# apollo4b register map
Vendor: Ambiq Micro; Series: Apollo; File version: 1.0
CPU: CM4 r1p0, little endian, MPU, FPU, I-cache, D-cache, VTOR, ITCM, DTCM, 3 interrupt priority bits, 0 interrupts
Registers are 32-bit, read-write, reset 0x0 unless marked. A register's access mark holds for its fields unless they carry their own. Offsets are from the block's base; [hi:lo] are bit positions; {n}, {i} and the like mark numbered series; 'fields as' and 'values as' point back to an identical list.

## GPIO (part 2 of 4) — General Purpose IO
Base 0x40010000
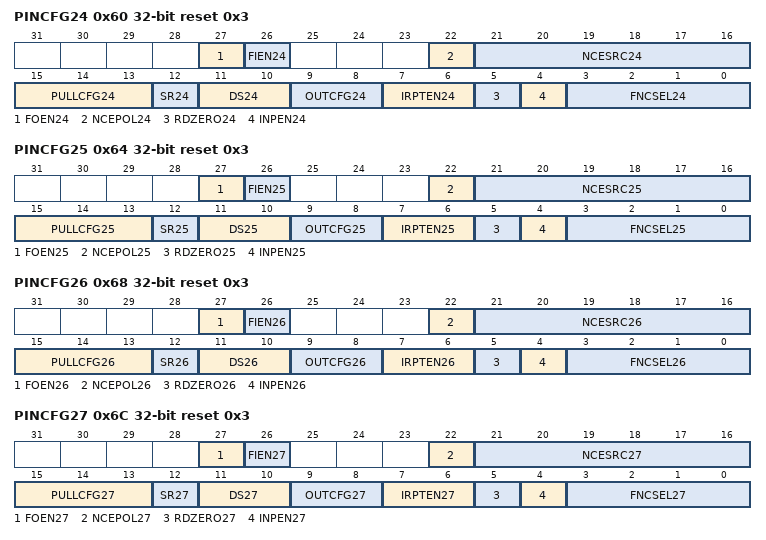
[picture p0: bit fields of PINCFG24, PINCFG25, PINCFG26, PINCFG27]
0x60 PINCFG24 reset 0x3 — Controls the operation of GPIO pin 24.
  [27] FOEN24 — Force output enable active regardless of function selected. Otherwise the selected function will enable the output only when needed
  [26] FIEN24 — Force input enable active regardless of function selected. Otherwise the selected function will enable the input only when needed
  [22] NCEPOL24 — Polarity select for NCE for GPIO 24
    0=LOW (Polarity is active low); 1=HIGH (Polarity is active high)
  [21:16] NCESRC24 — IOMSTR/MSPI N Chip Select 24, DISP control signals DE, CSX, and CS. Polarity is determined by CE_POLARITY field
    {v}=IOM0CE{v} (IOM 0 NCE {v} module) (v=0..3); {v}=IOM1CE{v-4} (IOM 1 NCE {v-4} module) (v=4..7); {v}=IOM2CE{v-8} (IOM 2 NCE {v-8} module) (v=8..11); {v}=IOM3CE{v-12} (IOM 3 NCE {v-12} module) (v=12..15); {v}=IOM4CE{v-16} (IOM 4 NCE {v-16} module) (v=16..19); {v}=IOM5CE{v-20} (IOM 5 NCE {v-20} module) (v=20..23); {v}=IOM6CE{v-24} (IOM 6 NCE {v-24} module) (v=24..27); {v}=IOM7CE{v-28} (IOM 7 NCE {v-28} module) (v=28..31); 32=MSPI0CEN0 (MSPI 0 NCE 0 module); 33=MSPI0CEN1 (MSPI 0 NCE 1 module); 34=MSPI1CEN0 (MSPI 1 NCE 0 module); 35=MSPI1CEN1 (MSPI 1 NCE 1 module); 36=MSPI2CEN0 (MSPI 2 NCE 0 module); 37=MSPI2CEN1 (MSPI 2 NCE 1 module); 38=DC_DPI_DE (DC DPI DE module); 39=DISP_CONT_CSX (DISP CONT CSX module); 40=DC_SPI_CS_N (DC SPI CS_N module); 41=DC_QSPI_CS_N (DC QSPI CS_N module); 42=DC_RESX (DC module RESX)
  [15:13] PULLCFG24 — Pullup/Pulldown configuration for GPIO 24
    0=DIS (No pullup or pulldown selected); 1=PD50K (50K Pulldown selected); 2=PU15K (1.5K Pullup selected); 3=PU6K (6K Pullup selected); 4=PU12K (12K Pullup selected); 5=PU24K (24K Pullup selected); 6=PU50K (50K Pullup selected); 7=PU100K (100K Pullup selected)
  [12] SR24 — Configure the slew rate
  [11:10] DS24 — Drive strength selection for GPIO 24
    0=0P1X (0.1x output driver selected); 1=0P5X (0.5x output driver selected); 2=0P75X (0.75x output driver selected); 3=1P0X (1.0x output driver selected)
  [9:8] OUTCFG24 — Pin IO mode selection for GPIO pin 24
    0=DIS (Output Disabled); 1=PUSHPULL (Output configured in push pull mode. Will drive 0 and 1 values on pin.); 2=OD (Output configured in open drain mode. Will only drive pin low, tristate otherwise.); 3=TS (Output configured in Tristate-able push pull mode. Will drive 0, 1 of HiZ on pin.)
  [7:6] IRPTEN24 — Interrupt enable for GPIO 24
    0=DIS (Interrupts are disabled for this GPIO); 1=INTFALL (Interrupts are enabled for falling edge transition on this GPIO); 2=INTRISE (Interrupts are enabled for rising edge transitions on this GPIO); 3=INTANY (Interrupts are enabled for any edge transition on this GPIO)
  [5] RDZERO24 — Return 0 for read data on GPIO 24
  [4] INPEN24 — Input enable for GPIO 24
  [3:0] FNCSEL24 — Function select for GPIO pin 24
    0=M7MISO (Serial SPI MASTER MISO input (IOM 7)); 1=TRIG3 (ADC trigger input); 2=SWO (Serial Wire Output); 3=GPIO (General purpose I/O); 4=UART0RTS (UART Request to Send (RTS) (UART 0)); 5=UART1RTS (UART Request to Send (RTS) (UART 1)); 6=CT24 (Timer/Counter input or output; Selection of direction is done via CTIMER register settings.); 7=NCE24 (IOMSTR/MSPI N Chip Select. Polarity is determined by CE_POLARITY field); 8=OBSBUS8 (Observation bus bit 8); 11=FPIO (Fast PIO); 15=SCANOUT7 (Internal function (SCAN))
0x64 PINCFG25 reset 0x3 — Controls the operation of GPIO pin 25.
  [27] FOEN25 — Force output enable active regardless of function selected. Otherwise the selected function will enable the output only when needed
  [26] FIEN25 — Force input enable active regardless of function selected. Otherwise the selected function will enable the input only when needed
  [22] NCEPOL25 — Polarity select for NCE for GPIO 25
    values as PINCFG24.NCEPOL24
  [21:16] NCESRC25 — IOMSTR/MSPI N Chip Select 25, DISP control signals DE, CSX, and CS. Polarity is determined by CE_POLARITY field
    values as PINCFG24.NCESRC24
  [15:13] PULLCFG25 — Pullup/Pulldown configuration for GPIO 25
    values as PINCFG24.PULLCFG24
  [12] SR25 — Configure the slew rate
  [11:10] DS25 — Drive strength selection for GPIO 25
    values as PINCFG24.DS24
  [9:8] OUTCFG25 — Pin IO mode selection for GPIO pin 25
    values as PINCFG24.OUTCFG24
  [7:6] IRPTEN25 — Interrupt enable for GPIO 25
    values as PINCFG24.IRPTEN24
  [5] RDZERO25 — Return 0 for read data on GPIO 25
  [4] INPEN25 — Input enable for GPIO 25
  [3:0] FNCSEL25 — Function select for GPIO pin 25
    0=M2SCL (Serial I2C Master Clock output (IOM 2)); 1=M2SCK (Serial SPI Master Clock output (IOM 2)); 3=GPIO (General purpose I/O); 4=LFRC_EXT (External LFRC Clock); 5=DSP_TMS (JTAG tms input); 6=CT25 (Timer/Counter input or output; Selection of direction is done via CTIMER register settings.); 7=NCE25 (IOMSTR/MSPI N Chip Select. Polarity is determined by CE_POLARITY field); 8=OBSBUS9 (Observation bus bit 9); 11=FPIO (Fast PIO); 15=SCANIN8 (Internal function (SCAN))
0x68 PINCFG26 reset 0x3 — Controls the operation of GPIO pin 26.
  [27] FOEN26 — Force output enable active regardless of function selected. Otherwise the selected function will enable the output only when needed
  [26] FIEN26 — Force input enable active regardless of function selected. Otherwise the selected function will enable the input only when needed
  [22] NCEPOL26 — Polarity select for NCE for GPIO 26
    values as PINCFG24.NCEPOL24
  [21:16] NCESRC26 — IOMSTR/MSPI N Chip Select 26, DISP control signals DE, CSX, and CS. Polarity is determined by CE_POLARITY field
    values as PINCFG24.NCESRC24
  [15:13] PULLCFG26 — Pullup/Pulldown configuration for GPIO 26
    values as PINCFG24.PULLCFG24
  [12] SR26 — Configure the slew rate
  [11:10] DS26 — Drive strength selection for GPIO 26
    values as PINCFG24.DS24
  [9:8] OUTCFG26 — Pin IO mode selection for GPIO pin 26
    values as PINCFG24.OUTCFG24
  [7:6] IRPTEN26 — Interrupt enable for GPIO 26
    values as PINCFG24.IRPTEN24
  [5] RDZERO26 — Return 0 for read data on GPIO 26
  [4] INPEN26 — Input enable for GPIO 26
  [3:0] FNCSEL26 — Function select for GPIO pin 26
    0=M2SDAWIR3 (Serial I2C Master Data I/O (I2C Mode) Serial SPI Master Data I/O (SPI 3 wire mode) (IOM 2)); 1=M2MOSI (Serial SPI Master MOSI output (IOM 2)); 3=GPIO (General purpose I/O); 4=HFRC_EXT (External HFRC Clock); 6=CT26 (Timer/Counter input or output; Selection of direction is done via CTIMER register settings.); 7=NCE26 (IOMSTR/MSPI N Chip Select. Polarity is determined by CE_POLARITY field); 8=OBSBUS10 (Observation bus bit 10); 9=VCMPO (Output of the voltage comparator signal); 11=FPIO (Fast PIO); 15=SCANIN9 (Internal function (SCAN))
0x6C PINCFG27 reset 0x3 — Controls the operation of GPIO pin 27.
  [27] FOEN27 — Force output enable active regardless of function selected. Otherwise the selected function will enable the output only when needed
  [26] FIEN27 — Force input enable active regardless of function selected. Otherwise the selected function will enable the input only when needed
  [22] NCEPOL27 — Polarity select for NCE for GPIO 27
    values as PINCFG24.NCEPOL24
  [21:16] NCESRC27 — IOMSTR/MSPI N Chip Select 27, DISP control signals DE, CSX, and CS. Polarity is determined by CE_POLARITY field
    values as PINCFG24.NCESRC24
  [15:13] PULLCFG27 — Pullup/Pulldown configuration for GPIO 27
    values as PINCFG24.PULLCFG24
  [12] SR27 — Configure the slew rate
  [11:10] DS27 — Drive strength selection for GPIO 27
    values as PINCFG24.DS24
  [9:8] OUTCFG27 — Pin IO mode selection for GPIO pin 27
    values as PINCFG24.OUTCFG24
  [7:6] IRPTEN27 — Interrupt enable for GPIO 27
    values as PINCFG24.IRPTEN24
  [5] RDZERO27 — Return 0 for read data on GPIO 27
  [4] INPEN27 — Input enable for GPIO 27
  [3:0] FNCSEL27 — Function select for GPIO pin 27
    0=M2MISO (Serial SPI MASTER MISO input (IOM 2)); 1=TRIG0 (ADC trigger input); 3=GPIO (General purpose I/O); 4=XT_EXT (External XT Clock); 5=DSP_TCK (JTAG tck clock interface); 6=CT27 (Timer/Counter input or output; Selection of direction is done via CTIMER register settings.); 7=NCE27 (IOMSTR/MSPI N Chip Select. Polarity is determined by CE_POLARITY field); 8=OBSBUS11 (Observation bus bit 11); 9=I2S0_SDIN (I2S Data input (I2S Master/Slave 2)); 11=FPIO (Fast PIO); 15=SCANIN10 (Internal function (SCAN))
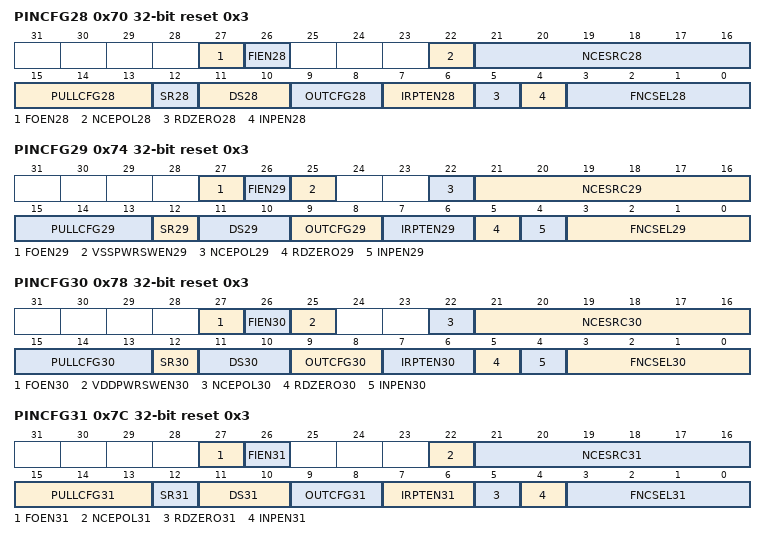
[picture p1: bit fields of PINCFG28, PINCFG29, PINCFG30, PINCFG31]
0x70 PINCFG28 reset 0x3 — Controls the operation of GPIO pin 28.
  [27] FOEN28 — Force output enable active regardless of function selected. Otherwise the selected function will enable the output only when needed
  [26] FIEN28 — Force input enable active regardless of function selected. Otherwise the selected function will enable the input only when needed
  [22] NCEPOL28 — Polarity select for NCE for GPIO 28
    values as PINCFG24.NCEPOL24
  [21:16] NCESRC28 — IOMSTR/MSPI N Chip Select 28, DISP control signals DE, CSX, and CS. Polarity is determined by CE_POLARITY field
    values as PINCFG24.NCESRC24
  [15:13] PULLCFG28 — Pullup/Pulldown configuration for GPIO 28
    values as PINCFG24.PULLCFG24
  [12] SR28 — Configure the slew rate
  [11:10] DS28 — Drive strength selection for GPIO 28
    0=0P1X (0.1x output driver selected); 1=0P5X (0.5x output driver selected)
  [9:8] OUTCFG28 — Pin IO mode selection for GPIO pin 28
    values as PINCFG24.OUTCFG24
  [7:6] IRPTEN28 — Interrupt enable for GPIO 28
    values as PINCFG24.IRPTEN24
  [5] RDZERO28 — Return 0 for read data on GPIO 28
  [4] INPEN28 — Input enable for GPIO 28
  [3:0] FNCSEL28 — Function select for GPIO pin 28
    0=SWO (Serial Wire Output); 1=VCMPO (Output of the voltage comparator signal); 2=I2S0_CLK (Bidirectional I2S Bit clock. Operates in output mode in master mode and input mode for slave mode. (I2S Master/Slave 2)); 3=GPIO (General purpose I/O); 4=UART2CTS (UART Clear to Send (CTS) (UART 2)); 5=DSP_TDO (JTAG tdo output); 6=CT28 (Timer/Counter input or output; Selection of direction is done via CTIMER register settings.); 7=NCE28 (IOMSTR/MSPI N Chip Select. Polarity is determined by CE_POLARITY field); 8=OBSBUS12 (Observation bus bit 12); 11=FPIO (Fast PIO); 15=CME (Internal function (SCAN))
0x74 PINCFG29 reset 0x3 — Controls the operation of GPIO pin 29.
  [27] FOEN29 — Force output enable active regardless of function selected. Otherwise the selected function will enable the output only when needed
  [26] FIEN29 — Force input enable active regardless of function selected. Otherwise the selected function will enable the input only when needed
  [25] VSSPWRSWEN29 — VSS power switch enable. Enable VSS power switch when driving pad signal to 0 for GPIO 29
    0=DIS (Power switch is disabled); 1=EN (Power switch is enabled)
  [22] NCEPOL29 — Polarity select for NCE for GPIO 29
    values as PINCFG24.NCEPOL24
  [21:16] NCESRC29 — IOMSTR/MSPI N Chip Select 29, DISP control signals DE, CSX, and CS. Polarity is determined by CE_POLARITY field
    values as PINCFG24.NCESRC24
  [15:13] PULLCFG29 — Pullup/Pulldown configuration for GPIO 29
    values as PINCFG24.PULLCFG24
  [12] SR29 — Configure the slew rate
  [11:10] DS29 — Drive strength selection for GPIO 29
    values as PINCFG28.DS28
  [9:8] OUTCFG29 — Pin IO mode selection for GPIO pin 29
    values as PINCFG24.OUTCFG24
  [7:6] IRPTEN29 — Interrupt enable for GPIO 29
    values as PINCFG24.IRPTEN24
  [5] RDZERO29 — Return 0 for read data on GPIO 29
  [4] INPEN29 — Input enable for GPIO 29
  [3:0] FNCSEL29 — Function select for GPIO pin 29
    0=TRIG0 (ADC trigger input); 1=VCMPO (Output of the voltage comparator signal); 2=I2S0_DATA (Bidirectional I2S Data. Operates in output mode in master mode and input mode for slave mode. (I2S Master/Slave 2)); 3=GPIO (General purpose I/O); 4=UART1CTS (UART Clear to Send (CTS) (UART 1)); 5=DSP_TRSTN (JTAG TRSTN input); 6=CT29 (Timer/Counter input or output; Selection of direction is done via CTIMER register settings.); 7=NCE29 (IOMSTR/MSPI N Chip Select. Polarity is determined by CE_POLARITY field); 8=OBSBUS13 (Observation bus bit 13); 9=I2S0_SDOUT (I2S Data output (I2S Master/Slave 2)); 11=FPIO (Fast PIO); 15=CMLE (Internal function (SCAN))
0x78 PINCFG30 reset 0x3 — Controls the operation of GPIO pin 30.
  [27] FOEN30 — Force output enable active regardless of function selected. Otherwise the selected function will enable the output only when needed
  [26] FIEN30 — Force input enable active regardless of function selected. Otherwise the selected function will enable the input only when needed
  [25] VDDPWRSWEN30 — VDD power switch enable. Enable VDD power switch when driving pad signal to 1 for GPIO 30
    values as PINCFG29.VSSPWRSWEN29
  [22] NCEPOL30 — Polarity select for NCE for GPIO 30
    values as PINCFG24.NCEPOL24
  [21:16] NCESRC30 — IOMSTR/MSPI N Chip Select 30, DISP control signals DE, CSX, and CS. Polarity is determined by CE_POLARITY field
    values as PINCFG24.NCESRC24
  [15:13] PULLCFG30 — Pullup/Pulldown configuration for GPIO 30
    values as PINCFG24.PULLCFG24
  [12] SR30 — Configure the slew rate
  [11:10] DS30 — Drive strength selection for GPIO 30
    values as PINCFG28.DS28
  [9:8] OUTCFG30 — Pin IO mode selection for GPIO pin 30
    values as PINCFG24.OUTCFG24
  [7:6] IRPTEN30 — Interrupt enable for GPIO 30
    values as PINCFG24.IRPTEN24
  [5] RDZERO30 — Return 0 for read data on GPIO 30
  [4] INPEN30 — Input enable for GPIO 30
  [3:0] FNCSEL30 — Function select for GPIO pin 30
    0=TRIG1 (ADC trigger input); 1=VCMPO (Output of the voltage comparator signal); 2=I2S0_WS (Bidirectional I2S L/R clock. Operates in output mode in master mode and input mode for slave mode. (I2S Master/Slave 2)); 3=GPIO (General purpose I/O); 4=UART0TX (UART transmit output (UART 0)); 5=DSP_TDI (JTAG tdi input); 6=CT30 (Timer/Counter input or output; Selection of direction is done via CTIMER register settings.); 7=NCE30 (IOMSTR/MSPI N Chip Select. Polarity is determined by CE_POLARITY field); 8=OBSBUS14 (Observation bus bit 14); 11=FPIO (Fast PIO); 15=SCANOUT8 (Internal function (SCAN))
0x7C PINCFG31 reset 0x3 — Controls the operation of GPIO pin 31.
  [27] FOEN31 — Force output enable active regardless of function selected. Otherwise the selected function will enable the output only when needed
  [26] FIEN31 — Force input enable active regardless of function selected. Otherwise the selected function will enable the input only when needed
  [22] NCEPOL31 — Polarity select for NCE for GPIO 31
    values as PINCFG24.NCEPOL24
  [21:16] NCESRC31 — IOMSTR/MSPI N Chip Select 31, DISP control signals DE, CSX, and CS. Polarity is determined by CE_POLARITY field
    values as PINCFG24.NCESRC24
  [15:13] PULLCFG31 — Pullup/Pulldown configuration for GPIO 31
    values as PINCFG24.PULLCFG24
  [12] SR31 — Configure the slew rate
  [11:10] DS31 — Drive strength selection for GPIO 31
    values as PINCFG24.DS24
  [9:8] OUTCFG31 — Pin IO mode selection for GPIO pin 31
    values as PINCFG24.OUTCFG24
  [7:6] IRPTEN31 — Interrupt enable for GPIO 31
    values as PINCFG24.IRPTEN24
  [5] RDZERO31 — Return 0 for read data on GPIO 31
  [4] INPEN31 — Input enable for GPIO 31
  [3:0] FNCSEL31 — Function select for GPIO pin 31
    0=M3SCL (Serial I2C Master Clock output (IOM 3)); 1=M3SCK (Serial SPI Master Clock output (IOM 3)); 3=GPIO (General purpose I/O); 4=UART2TX (UART transmit output (UART 2)); 6=CT31 (Timer/Counter input or output; Selection of direction is done via CTIMER register settings.); 7=NCE31 (IOMSTR/MSPI N Chip Select. Polarity is determined by CE_POLARITY field); 8=OBSBUS15 (Observation bus bit 15); 9=VCMPO (Output of the voltage comparator signal); 11=FPIO (Fast PIO); 15=SCANOUT9 (Internal function (SCAN))
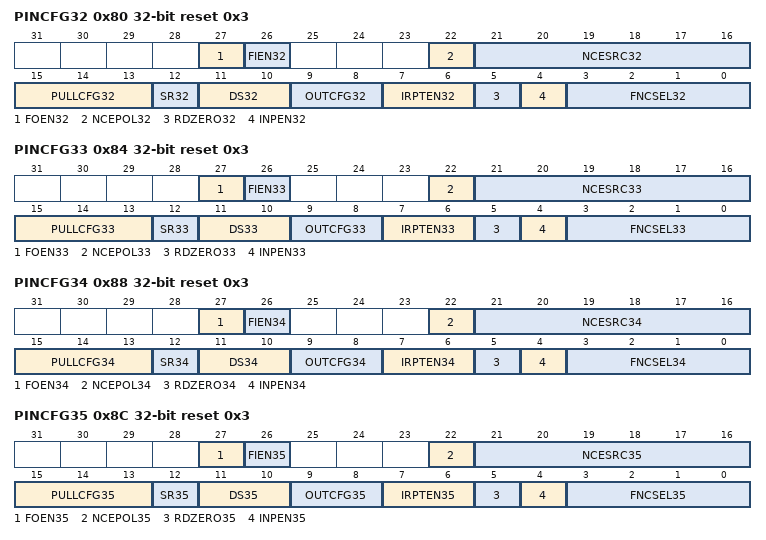
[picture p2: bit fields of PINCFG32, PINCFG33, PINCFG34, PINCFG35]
0x80 PINCFG32 reset 0x3 — Controls the operation of GPIO pin 32.
  [27] FOEN32 — Force output enable active regardless of function selected. Otherwise the selected function will enable the output only when needed
  [26] FIEN32 — Force input enable active regardless of function selected. Otherwise the selected function will enable the input only when needed
  [22] NCEPOL32 — Polarity select for NCE for GPIO 32
    values as PINCFG24.NCEPOL24
  [21:16] NCESRC32 — IOMSTR/MSPI N Chip Select 32, DISP control signals DE, CSX, and CS. Polarity is determined by CE_POLARITY field
    values as PINCFG24.NCESRC24
  [15:13] PULLCFG32 — Pullup/Pulldown configuration for GPIO 32
    values as PINCFG24.PULLCFG24
  [12] SR32 — Configure the slew rate
  [11:10] DS32 — Drive strength selection for GPIO 32
    values as PINCFG24.DS24
  [9:8] OUTCFG32 — Pin IO mode selection for GPIO pin 32
    values as PINCFG24.OUTCFG24
  [7:6] IRPTEN32 — Interrupt enable for GPIO 32
    values as PINCFG24.IRPTEN24
  [5] RDZERO32 — Return 0 for read data on GPIO 32
  [4] INPEN32 — Input enable for GPIO 32
  [3:0] FNCSEL32 — Function select for GPIO pin 32
    0=M3SDAWIR3 (Serial I2C Master Data I/O (I2C Mode) Serial SPI Master Data I/O (SPI 3 wire mode) (IOM 3)); 1=M3MOSI (Serial SPI Master MOSI output (IOM 3)); 3=GPIO (General purpose I/O); 4=UART0RX (UART receive input (UART 0)); 6=CT32 (Timer/Counter input or output; Selection of direction is done via CTIMER register settings.); 7=NCE32 (IOMSTR/MSPI N Chip Select. Polarity is determined by CE_POLARITY field); 8=OBSBUS0 (Observation bus bit 0); 11=FPIO (Fast PIO); 15=SCANOUT10 (Internal function (SCAN))
0x84 PINCFG33 reset 0x3 — Controls the operation of GPIO pin 33.
  [27] FOEN33 — Force output enable active regardless of function selected. Otherwise the selected function will enable the output only when needed
  [26] FIEN33 — Force input enable active regardless of function selected. Otherwise the selected function will enable the input only when needed
  [22] NCEPOL33 — Polarity select for NCE for GPIO 33
    values as PINCFG24.NCEPOL24
  [21:16] NCESRC33 — IOMSTR/MSPI N Chip Select 33, DISP control signals DE, CSX, and CS. Polarity is determined by CE_POLARITY field
    values as PINCFG24.NCESRC24
  [15:13] PULLCFG33 — Pullup/Pulldown configuration for GPIO 33
    values as PINCFG24.PULLCFG24
  [12] SR33 — Configure the slew rate
  [11:10] DS33 — Drive strength selection for GPIO 33
    values as PINCFG24.DS24
  [9:8] OUTCFG33 — Pin IO mode selection for GPIO pin 33
    values as PINCFG24.OUTCFG24
  [7:6] IRPTEN33 — Interrupt enable for GPIO 33
    values as PINCFG24.IRPTEN24
  [5] RDZERO33 — Return 0 for read data on GPIO 33
  [4] INPEN33 — Input enable for GPIO 33
  [3:0] FNCSEL33 — Function select for GPIO pin 33
    0=M3MISO (Serial SPI MASTER MISO input (IOM 3)); 1=CLKOUT (Oscillator output clock); 3=GPIO (General purpose I/O); 4=UART2RX (UART receive input (UART 2)); 6=CT33 (Timer/Counter input or output; Selection of direction is done via CTIMER register settings.); 7=NCE33 (IOMSTR/MSPI N Chip Select. Polarity is determined by CE_POLARITY field); 8=OBSBUS1 (Observation bus bit 1); 9=DISP_TE (Display TE input); 11=FPIO (Fast PIO); 15=SCANOUT11 (Internal function (SCAN))
0x88 PINCFG34 reset 0x3 — Controls the operation of GPIO pin 34.
  [27] FOEN34 — Force output enable active regardless of function selected. Otherwise the selected function will enable the output only when needed
  [26] FIEN34 — Force input enable active regardless of function selected. Otherwise the selected function will enable the input only when needed
  [22] NCEPOL34 — Polarity select for NCE for GPIO 34
    values as PINCFG24.NCEPOL24
  [21:16] NCESRC34 — IOMSTR/MSPI N Chip Select 34, DISP control signals DE, CSX, and CS. Polarity is determined by CE_POLARITY field
    values as PINCFG24.NCESRC24
  [15:13] PULLCFG34 — Pullup/Pulldown configuration for GPIO 34
    values as PINCFG24.PULLCFG24
  [12] SR34 — Configure the slew rate
  [11:10] DS34 — Drive strength selection for GPIO 34
    values as PINCFG24.DS24
  [9:8] OUTCFG34 — Pin IO mode selection for GPIO pin 34
    values as PINCFG24.OUTCFG24
  [7:6] IRPTEN34 — Interrupt enable for GPIO 34
    values as PINCFG24.IRPTEN24
  [5] RDZERO34 — Return 0 for read data on GPIO 34
  [4] INPEN34 — Input enable for GPIO 34
  [3:0] FNCSEL34 — Function select for GPIO pin 34
    0=M4SCL (Serial I2C Master Clock output (IOM 4)); 1=M4SCK (Serial SPI Master Clock output (IOM 4)); 2=SWO (Serial Wire Output); 3=GPIO (General purpose I/O); 4=UART0TX (UART transmit output (UART 0)); 6=CT34 (Timer/Counter input or output; Selection of direction is done via CTIMER register settings.); 7=NCE34 (IOMSTR/MSPI N Chip Select. Polarity is determined by CE_POLARITY field); 8=OBSBUS2 (Observation bus bit 2); 9=VCMPO (Output of the voltage comparator signal); 11=FPIO (Fast PIO)
0x8C PINCFG35 reset 0x3 — Controls the operation of GPIO pin 35.
  [27] FOEN35 — Force output enable active regardless of function selected. Otherwise the selected function will enable the output only when needed
  [26] FIEN35 — Force input enable active regardless of function selected. Otherwise the selected function will enable the input only when needed
  [22] NCEPOL35 — Polarity select for NCE for GPIO 35
    values as PINCFG24.NCEPOL24
  [21:16] NCESRC35 — IOMSTR/MSPI N Chip Select 35, DISP control signals DE, CSX, and CS. Polarity is determined by CE_POLARITY field
    values as PINCFG24.NCESRC24
  [15:13] PULLCFG35 — Pullup/Pulldown configuration for GPIO 35
    values as PINCFG24.PULLCFG24
  [12] SR35 — Configure the slew rate
  [11:10] DS35 — Drive strength selection for GPIO 35
    values as PINCFG24.DS24
  [9:8] OUTCFG35 — Pin IO mode selection for GPIO pin 35
    values as PINCFG24.OUTCFG24
  [7:6] IRPTEN35 — Interrupt enable for GPIO 35
    values as PINCFG24.IRPTEN24
  [5] RDZERO35 — Return 0 for read data on GPIO 35
  [4] INPEN35 — Input enable for GPIO 35
  [3:0] FNCSEL35 — Function select for GPIO pin 35
    0=M4SDAWIR3 (Serial I2C Master Data I/O (I2C Mode) Serial SPI Master Data I/O (SPI 3 wire mode) (IOM 4)); 1=M4MOSI (Serial SPI Master MOSI output (IOM 4)); 2=SWO (Serial Wire Output); 3=GPIO (General purpose I/O); 4=UART2TX (UART transmit output (UART 2)); 5=UART3TX (UART transmit output (UART 3)); 6=CT35 (Timer/Counter input or output; Selection of direction is done via CTIMER register settings.); 7=NCE35 (IOMSTR/MSPI N Chip Select. Polarity is determined by CE_POLARITY field); 8=OBSBUS3 (Observation bus bit 3); 9=VCMPO (Output of the voltage comparator signal); 11=FPIO (Fast PIO)
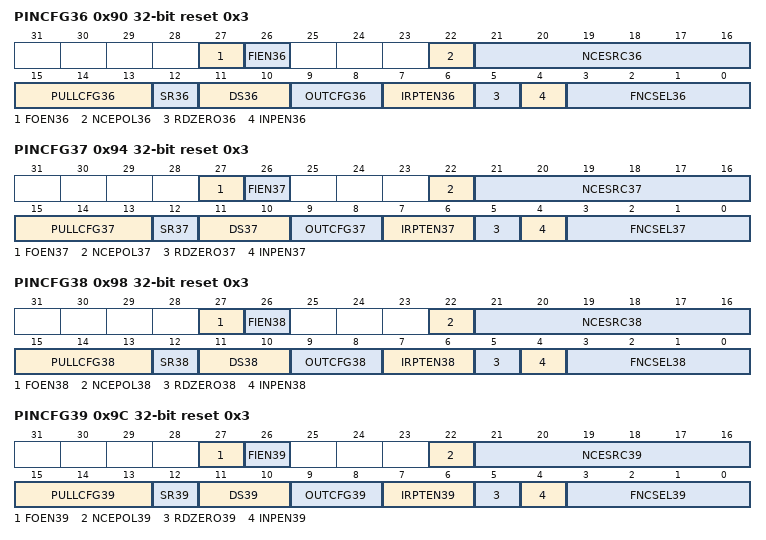
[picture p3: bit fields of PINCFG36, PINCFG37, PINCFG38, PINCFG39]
0x90 PINCFG36 reset 0x3 — Controls the operation of GPIO pin 36.
  [27] FOEN36 — Force output enable active regardless of function selected. Otherwise the selected function will enable the output only when needed
  [26] FIEN36 — Force input enable active regardless of function selected. Otherwise the selected function will enable the input only when needed
  [22] NCEPOL36 — Polarity select for NCE for GPIO 36
    values as PINCFG24.NCEPOL24
  [21:16] NCESRC36 — IOMSTR/MSPI N Chip Select 36, DISP control signals DE, CSX, and CS. Polarity is determined by CE_POLARITY field
    values as PINCFG24.NCESRC24
  [15:13] PULLCFG36 — Pullup/Pulldown configuration for GPIO 36
    values as PINCFG24.PULLCFG24
  [12] SR36 — Configure the slew rate
  [11:10] DS36 — Drive strength selection for GPIO 36
    values as PINCFG24.DS24
  [9:8] OUTCFG36 — Pin IO mode selection for GPIO pin 36
    values as PINCFG24.OUTCFG24
  [7:6] IRPTEN36 — Interrupt enable for GPIO 36
    values as PINCFG24.IRPTEN24
  [5] RDZERO36 — Return 0 for read data on GPIO 36
  [4] INPEN36 — Input enable for GPIO 36
  [3:0] FNCSEL36 — Function select for GPIO pin 36
    0=M4MISO (Serial SPI MASTER MISO input (IOM 4)); 1=TRIG0 (ADC trigger input); 2=SWO (Serial Wire Output); 3=GPIO (General purpose I/O); 4=UART0RX (UART receive input (UART 0)); 5=UART1RX (UART receive input (UART 1)); 6=CT36 (Timer/Counter input or output; Selection of direction is done via CTIMER register settings.); 7=NCE36 (IOMSTR/MSPI N Chip Select. Polarity is determined by CE_POLARITY field); 8=OBSBUS4 (Observation bus bit 4); 11=FPIO (Fast PIO)
0x94 PINCFG37 reset 0x3 — Controls the operation of GPIO pin 37.
  [27] FOEN37 — Force output enable active regardless of function selected. Otherwise the selected function will enable the output only when needed
  [26] FIEN37 — Force input enable active regardless of function selected. Otherwise the selected function will enable the input only when needed
  [22] NCEPOL37 — Polarity select for NCE for GPIO 37
    values as PINCFG24.NCEPOL24
  [21:16] NCESRC37 — IOMSTR/MSPI N Chip Select 37, DISP control signals DE, CSX, and CS. Polarity is determined by CE_POLARITY field
    values as PINCFG24.NCESRC24
  [15:13] PULLCFG37 — Pullup/Pulldown configuration for GPIO 37
    values as PINCFG24.PULLCFG24
  [12] SR37 — Configure the slew rate
  [11:10] DS37 — Drive strength selection for GPIO 37
    values as PINCFG24.DS24
  [9:8] OUTCFG37 — Pin IO mode selection for GPIO pin 37
    values as PINCFG24.OUTCFG24
  [7:6] IRPTEN37 — Interrupt enable for GPIO 37
    values as PINCFG24.IRPTEN24
  [5] RDZERO37 — Return 0 for read data on GPIO 37
  [4] INPEN37 — Input enable for GPIO 37
  [3:0] FNCSEL37 — Function select for GPIO pin 37
    0=MSPI1_0 (MSPI Master 1 Interface Signal); 1=TRIG1 (ADC trigger input); 2=32KHzXT (32kHZ from analog); 3=GPIO (General purpose I/O); 4=UART2RX (UART receive input (UART 2)); 5=DISP_D15 (Display Data 15); 6=CT37 (Timer/Counter input or output; Selection of direction is done via CTIMER register settings.); 7=NCE37 (IOMSTR/MSPI N Chip Select. Polarity is determined by CE_POLARITY field); 8=OBSBUS5 (Observation bus bit 5); 11=FPIO (Fast PIO)
0x98 PINCFG38 reset 0x3 — Controls the operation of GPIO pin 38.
  [27] FOEN38 — Force output enable active regardless of function selected. Otherwise the selected function will enable the output only when needed
  [26] FIEN38 — Force input enable active regardless of function selected. Otherwise the selected function will enable the input only when needed
  [22] NCEPOL38 — Polarity select for NCE for GPIO 38
    values as PINCFG24.NCEPOL24
  [21:16] NCESRC38 — IOMSTR/MSPI N Chip Select 38, DISP control signals DE, CSX, and CS. Polarity is determined by CE_POLARITY field
    values as PINCFG24.NCESRC24
  [15:13] PULLCFG38 — Pullup/Pulldown configuration for GPIO 38
    values as PINCFG24.PULLCFG24
  [12] SR38 — Configure the slew rate
  [11:10] DS38 — Drive strength selection for GPIO 38
    values as PINCFG24.DS24
  [9:8] OUTCFG38 — Pin IO mode selection for GPIO pin 38
    values as PINCFG24.OUTCFG24
  [7:6] IRPTEN38 — Interrupt enable for GPIO 38
    values as PINCFG24.IRPTEN24
  [5] RDZERO38 — Return 0 for read data on GPIO 38
  [4] INPEN38 — Input enable for GPIO 38
  [3:0] FNCSEL38 — Function select for GPIO pin 38
    0=MSPI1_1 (MSPI Master 1 Interface Signal); 1=TRIG2 (ADC trigger input); 2=SWTRACECLK (Serial Wire Debug Trace Clock); 3=GPIO (General purpose I/O); 4=UART0RTS (UART Request to Send (RTS) (UART 0)); 5=DISP_D16 (Display Data 16); 6=CT38 (Timer/Counter input or output; Selection of direction is done via CTIMER register settings.); 7=NCE38 (IOMSTR/MSPI N Chip Select. Polarity is determined by CE_POLARITY field); 8=OBSBUS6 (Observation bus bit 6); 11=FPIO (Fast PIO)
0x9C PINCFG39 reset 0x3 — Controls the operation of GPIO pin 39.
  [27] FOEN39 — Force output enable active regardless of function selected. Otherwise the selected function will enable the output only when needed
  [26] FIEN39 — Force input enable active regardless of function selected. Otherwise the selected function will enable the input only when needed
  [22] NCEPOL39 — Polarity select for NCE for GPIO 39
    values as PINCFG24.NCEPOL24
  [21:16] NCESRC39 — IOMSTR/MSPI N Chip Select 39, DISP control signals DE, CSX, and CS. Polarity is determined by CE_POLARITY field
    values as PINCFG24.NCESRC24
  [15:13] PULLCFG39 — Pullup/Pulldown configuration for GPIO 39
    values as PINCFG24.PULLCFG24
  [12] SR39 — Configure the slew rate
  [11:10] DS39 — Drive strength selection for GPIO 39
    values as PINCFG24.DS24
  [9:8] OUTCFG39 — Pin IO mode selection for GPIO pin 39
    values as PINCFG24.OUTCFG24
  [7:6] IRPTEN39 — Interrupt enable for GPIO 39
    values as PINCFG24.IRPTEN24
  [5] RDZERO39 — Return 0 for read data on GPIO 39
  [4] INPEN39 — Input enable for GPIO 39
  [3:0] FNCSEL39 — Function select for GPIO pin 39
    0=MSPI1_2 (MSPI Master 1 Interface Signal); 1=TRIG3 (ADC trigger input); 2=SWTRACE0 (Serial Wire Debug Trace Output 0); 3=GPIO (General purpose I/O); 4=UART2RTS (UART Request to Send (RTS) (UART 2)); 5=DISP_D17 (Display Data 17); 6=CT39 (Timer/Counter input or output; Selection of direction is done via CTIMER register settings.); 7=NCE39 (IOMSTR/MSPI N Chip Select. Polarity is determined by CE_POLARITY field); 8=OBSBUS7 (Observation bus bit 7); 11=FPIO (Fast PIO)
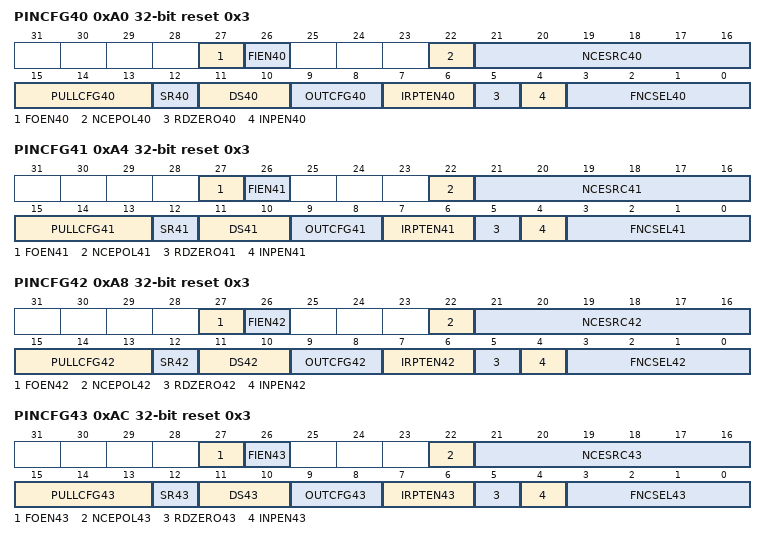
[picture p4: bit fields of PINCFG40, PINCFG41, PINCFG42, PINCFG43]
0xA0 PINCFG40 reset 0x3 — Controls the operation of GPIO pin 40.
  [27] FOEN40 — Force output enable active regardless of function selected. Otherwise the selected function will enable the output only when needed
  [26] FIEN40 — Force input enable active regardless of function selected. Otherwise the selected function will enable the input only when needed
  [22] NCEPOL40 — Polarity select for NCE for GPIO 40
    values as PINCFG24.NCEPOL24
  [21:16] NCESRC40 — IOMSTR/MSPI N Chip Select 40, DISP control signals DE, CSX, and CS. Polarity is determined by CE_POLARITY field
    values as PINCFG24.NCESRC24
  [15:13] PULLCFG40 — Pullup/Pulldown configuration for GPIO 40
    values as PINCFG24.PULLCFG24
  [12] SR40 — Configure the slew rate
  [11:10] DS40 — Drive strength selection for GPIO 40
    values as PINCFG24.DS24
  [9:8] OUTCFG40 — Pin IO mode selection for GPIO pin 40
    values as PINCFG24.OUTCFG24
  [7:6] IRPTEN40 — Interrupt enable for GPIO 40
    values as PINCFG24.IRPTEN24
  [5] RDZERO40 — Return 0 for read data on GPIO 40
  [4] INPEN40 — Input enable for GPIO 40
  [3:0] FNCSEL40 — Function select for GPIO pin 40
    0=MSPI1_3 (MSPI Master 1 Interface Signal); 1=TRIG1 (ADC trigger input); 2=SWTRACE1 (Serial Wire Debug Trace Output 1); 3=GPIO (General purpose I/O); 4=UART0CTS (UART Clear to Send (CTS) (UART 0)); 5=DISP_D18 (Display Data 18); 6=CT40 (Timer/Counter input or output; Selection of direction is done via CTIMER register settings.); 7=NCE40 (IOMSTR/MSPI N Chip Select. Polarity is determined by CE_POLARITY field); 8=OBSBUS8 (Observation bus bit 8); 11=FPIO (Fast PIO)
0xA4 PINCFG41 reset 0x3 — Controls the operation of GPIO pin 41.
  [27] FOEN41 — Force output enable active regardless of function selected. Otherwise the selected function will enable the output only when needed
  [26] FIEN41 — Force input enable active regardless of function selected. Otherwise the selected function will enable the input only when needed
  [22] NCEPOL41 — Polarity select for NCE for GPIO 41
    values as PINCFG24.NCEPOL24
  [21:16] NCESRC41 — IOMSTR/MSPI N Chip Select 41, DISP control signals DE, CSX, and CS. Polarity is determined by CE_POLARITY field
    values as PINCFG24.NCESRC24
  [15:13] PULLCFG41 — Pullup/Pulldown configuration for GPIO 41
    values as PINCFG24.PULLCFG24
  [12] SR41 — Configure the slew rate
  [11:10] DS41 — Drive strength selection for GPIO 41
    values as PINCFG24.DS24
  [9:8] OUTCFG41 — Pin IO mode selection for GPIO pin 41
    values as PINCFG24.OUTCFG24
  [7:6] IRPTEN41 — Interrupt enable for GPIO 41
    values as PINCFG24.IRPTEN24
  [5] RDZERO41 — Return 0 for read data on GPIO 41
  [4] INPEN41 — Input enable for GPIO 41
  [3:0] FNCSEL41 — Function select for GPIO pin 41
    0=MSPI1_4 (MSPI Master 1 Interface Signal); 1=TRIG0 (ADC trigger input); 2=SWTRACE2 (Serial Wire Debug Trace Output 2); 3=GPIO (General purpose I/O); 4=UART0TX (UART transmit output (UART 0)); 5=DISP_D19 (Display Data 19); 6=CT41 (Timer/Counter input or output; Selection of direction is done via CTIMER register settings.); 7=NCE41 (IOMSTR/MSPI N Chip Select. Polarity is determined by CE_POLARITY field); 8=OBSBUS9 (Observation bus bit 9); 9=SWO (Serial Wire Output); 11=FPIO (Fast PIO)
0xA8 PINCFG42 reset 0x3 — Controls the operation of GPIO pin 42.
  [27] FOEN42 — Force output enable active regardless of function selected. Otherwise the selected function will enable the output only when needed
  [26] FIEN42 — Force input enable active regardless of function selected. Otherwise the selected function will enable the input only when needed
  [22] NCEPOL42 — Polarity select for NCE for GPIO 42
    values as PINCFG24.NCEPOL24
  [21:16] NCESRC42 — IOMSTR/MSPI N Chip Select 42, DISP control signals DE, CSX, and CS. Polarity is determined by CE_POLARITY field
    values as PINCFG24.NCESRC24
  [15:13] PULLCFG42 — Pullup/Pulldown configuration for GPIO 42
    values as PINCFG24.PULLCFG24
  [12] SR42 — Configure the slew rate
  [11:10] DS42 — Drive strength selection for GPIO 42
    values as PINCFG24.DS24
  [9:8] OUTCFG42 — Pin IO mode selection for GPIO pin 42
    values as PINCFG24.OUTCFG24
  [7:6] IRPTEN42 — Interrupt enable for GPIO 42
    values as PINCFG24.IRPTEN24
  [5] RDZERO42 — Return 0 for read data on GPIO 42
  [4] INPEN42 — Input enable for GPIO 42
  [3:0] FNCSEL42 — Function select for GPIO pin 42
    0=MSPI1_5 (MSPI Master 1 Interface Signal); 1=TRIG2 (ADC trigger input); 2=SWTRACE3 (Serial Wire Debug Trace Output 3); 3=GPIO (General purpose I/O); 4=UART2TX (UART transmit output (UART 2)); 5=DISP_D20 (Display Data 20); 6=CT42 (Timer/Counter input or output; Selection of direction is done via CTIMER register settings.); 7=NCE42 (IOMSTR/MSPI N Chip Select. Polarity is determined by CE_POLARITY field); 8=OBSBUS10 (Observation bus bit 10); 11=FPIO (Fast PIO)
0xAC PINCFG43 reset 0x3 — Controls the operation of GPIO pin 43.
  [27] FOEN43 — Force output enable active regardless of function selected. Otherwise the selected function will enable the output only when needed
  [26] FIEN43 — Force input enable active regardless of function selected. Otherwise the selected function will enable the input only when needed
  [22] NCEPOL43 — Polarity select for NCE for GPIO 43
    values as PINCFG24.NCEPOL24
  [21:16] NCESRC43 — IOMSTR/MSPI N Chip Select 43, DISP control signals DE, CSX, and CS. Polarity is determined by CE_POLARITY field
    values as PINCFG24.NCESRC24
  [15:13] PULLCFG43 — Pullup/Pulldown configuration for GPIO 43
    values as PINCFG24.PULLCFG24
  [12] SR43 — Configure the slew rate
  [11:10] DS43 — Drive strength selection for GPIO 43
    values as PINCFG24.DS24
  [9:8] OUTCFG43 — Pin IO mode selection for GPIO pin 43
    values as PINCFG24.OUTCFG24
  [7:6] IRPTEN43 — Interrupt enable for GPIO 43
    values as PINCFG24.IRPTEN24
  [5] RDZERO43 — Return 0 for read data on GPIO 43
  [4] INPEN43 — Input enable for GPIO 43
  [3:0] FNCSEL43 — Function select for GPIO pin 43
    0=MSPI1_6 (MSPI Master 1 Interface Signal); 1=TRIG3 (ADC trigger input); 2=SWTRACECTL (Serial Wire Debug Trace Control); 3=GPIO (General purpose I/O); 4=UART0RX (UART receive input (UART 0)); 5=DISP_D21 (Display Data 21); 6=CT43 (Timer/Counter input or output; Selection of direction is done via CTIMER register settings.); 7=NCE43 (IOMSTR/MSPI N Chip Select. Polarity is determined by CE_POLARITY field); 8=OBSBUS11 (Observation bus bit 11); 11=FPIO (Fast PIO)
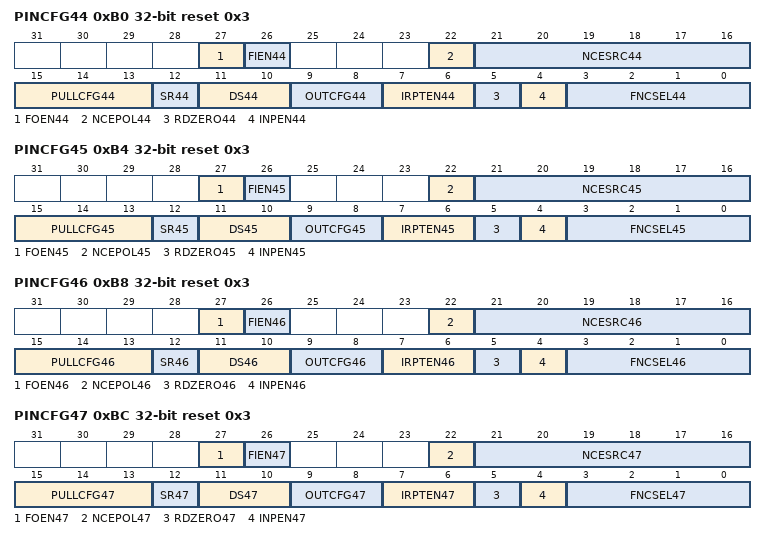
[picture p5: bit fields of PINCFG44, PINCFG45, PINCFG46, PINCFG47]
0xB0 PINCFG44 reset 0x3 — Controls the operation of GPIO pin 44.
  [27] FOEN44 — Force output enable active regardless of function selected. Otherwise the selected function will enable the output only when needed
  [26] FIEN44 — Force input enable active regardless of function selected. Otherwise the selected function will enable the input only when needed
  [22] NCEPOL44 — Polarity select for NCE for GPIO 44
    values as PINCFG24.NCEPOL24
  [21:16] NCESRC44 — IOMSTR/MSPI N Chip Select 44, DISP control signals DE, CSX, and CS. Polarity is determined by CE_POLARITY field
    values as PINCFG24.NCESRC24
  [15:13] PULLCFG44 — Pullup/Pulldown configuration for GPIO 44
    values as PINCFG24.PULLCFG24
  [12] SR44 — Configure the slew rate
  [11:10] DS44 — Drive strength selection for GPIO 44
    values as PINCFG24.DS24
  [9:8] OUTCFG44 — Pin IO mode selection for GPIO pin 44
    values as PINCFG24.OUTCFG24
  [7:6] IRPTEN44 — Interrupt enable for GPIO 44
    values as PINCFG24.IRPTEN24
  [5] RDZERO44 — Return 0 for read data on GPIO 44
  [4] INPEN44 — Input enable for GPIO 44
  [3:0] FNCSEL44 — Function select for GPIO pin 44
    0=MSPI1_7 (MSPI Master 1 Interface Signal); 1=TRIG1 (ADC trigger input); 2=SWO (Serial Wire Output); 3=GPIO (General purpose I/O); 4=UART2RX (UART receive input (UART 2)); 5=DISP_D22 (Display Data 22); 6=CT44 (Timer/Counter input or output; Selection of direction is done via CTIMER register settings.); 7=NCE44 (IOMSTR/MSPI N Chip Select. Polarity is determined by CE_POLARITY field); 8=OBSBUS12 (Observation bus bit 12); 9=VCMPO (Output of the voltage comparator signal); 11=FPIO (Fast PIO)
0xB4 PINCFG45 reset 0x3 — Controls the operation of GPIO pin 45.
  [27] FOEN45 — Force output enable active regardless of function selected. Otherwise the selected function will enable the output only when needed
  [26] FIEN45 — Force input enable active regardless of function selected. Otherwise the selected function will enable the input only when needed
  [22] NCEPOL45 — Polarity select for NCE for GPIO 45
    values as PINCFG24.NCEPOL24
  [21:16] NCESRC45 — IOMSTR/MSPI N Chip Select 45, DISP control signals DE, CSX, and CS. Polarity is determined by CE_POLARITY field
    values as PINCFG24.NCESRC24
  [15:13] PULLCFG45 — Pullup/Pulldown configuration for GPIO 45
    values as PINCFG24.PULLCFG24
  [12] SR45 — Configure the slew rate
  [11:10] DS45 — Drive strength selection for GPIO 45
    values as PINCFG24.DS24
  [9:8] OUTCFG45 — Pin IO mode selection for GPIO pin 45
    values as PINCFG24.OUTCFG24
  [7:6] IRPTEN45 — Interrupt enable for GPIO 45
    values as PINCFG24.IRPTEN24
  [5] RDZERO45 — Return 0 for read data on GPIO 45
  [4] INPEN45 — Input enable for GPIO 45
  [3:0] FNCSEL45 — Function select for GPIO pin 45
    0=MSPI1_8 (MSPI Master 1 Interface Signal); 1=TRIG2 (ADC trigger input); 2=32KHzXT (32kHZ from analog); 3=GPIO (General purpose I/O); 4=UART0TX (UART transmit output (UART 0)); 5=DISP_D23 (Display Data 23); 6=CT45 (Timer/Counter input or output; Selection of direction is done via CTIMER register settings.); 7=NCE45 (IOMSTR/MSPI N Chip Select. Polarity is determined by CE_POLARITY field); 8=OBSBUS13 (Observation bus bit 13); 11=FPIO (Fast PIO)
0xB8 PINCFG46 reset 0x3 — Controls the operation of GPIO pin 46.
  [27] FOEN46 — Force output enable active regardless of function selected. Otherwise the selected function will enable the output only when needed
  [26] FIEN46 — Force input enable active regardless of function selected. Otherwise the selected function will enable the input only when needed
  [22] NCEPOL46 — Polarity select for NCE for GPIO 46
    values as PINCFG24.NCEPOL24
  [21:16] NCESRC46 — IOMSTR/MSPI N Chip Select 46, DISP control signals DE, CSX, and CS. Polarity is determined by CE_POLARITY field
    values as PINCFG24.NCESRC24
  [15:13] PULLCFG46 — Pullup/Pulldown configuration for GPIO 46
    values as PINCFG24.PULLCFG24
  [12] SR46 — Configure the slew rate
  [11:10] DS46 — Drive strength selection for GPIO 46
    values as PINCFG24.DS24
  [9:8] OUTCFG46 — Pin IO mode selection for GPIO pin 46
    values as PINCFG24.OUTCFG24
  [7:6] IRPTEN46 — Interrupt enable for GPIO 46
    values as PINCFG24.IRPTEN24
  [5] RDZERO46 — Return 0 for read data on GPIO 46
  [4] INPEN46 — Input enable for GPIO 46
  [3:0] FNCSEL46 — Function select for GPIO pin 46
    0=MSPI1_9 (MSPI Master 1 Interface Signal); 1=TRIG3 (ADC trigger input); 2=CLKOUT_32M (32MHz Oscillator output clock); 3=GPIO (General purpose I/O); 4=UART2TX (UART transmit output (UART 2)); 5=UART3TX (UART transmit output (UART 3)); 6=CT46 (Timer/Counter input or output; Selection of direction is done via CTIMER register settings.); 7=NCE46 (IOMSTR/MSPI N Chip Select. Polarity is determined by CE_POLARITY field); 8=OBSBUS14 (Observation bus bit 14); 9=I2S1_SDIN (I2S Data input (I2S Master/Slave 2)); 10=I2S0_SDIN (I2S Data input (I2S Master/Slave 2)); 11=FPIO (Fast PIO)
0xBC PINCFG47 reset 0x3 — Controls the operation of GPIO pin 47.
  [27] FOEN47 — Force output enable active regardless of function selected. Otherwise the selected function will enable the output only when needed
  [26] FIEN47 — Force input enable active regardless of function selected. Otherwise the selected function will enable the input only when needed
  [22] NCEPOL47 — Polarity select for NCE for GPIO 47
    values as PINCFG24.NCEPOL24
  [21:16] NCESRC47 — IOMSTR/MSPI N Chip Select 47, DISP control signals DE, CSX, and CS. Polarity is determined by CE_POLARITY field
    values as PINCFG24.NCESRC24
  [15:13] PULLCFG47 — Pullup/Pulldown configuration for GPIO 47
    values as PINCFG24.PULLCFG24
  [12] SR47 — Configure the slew rate
  [11:10] DS47 — Drive strength selection for GPIO 47
    values as PINCFG24.DS24
  [9:8] OUTCFG47 — Pin IO mode selection for GPIO pin 47
    values as PINCFG24.OUTCFG24
  [7:6] IRPTEN47 — Interrupt enable for GPIO 47
    values as PINCFG24.IRPTEN24
  [5] RDZERO47 — Return 0 for read data on GPIO 47
  [4] INPEN47 — Input enable for GPIO 47
  [3:0] FNCSEL47 — Function select for GPIO pin 47
    0=M5SCL (Serial I2C Master Clock output (IOM 5)); 1=M5SCK (Serial SPI Master Clock output (IOM 5)); 2=I2S1_CLK (Bidirectional I2S Bit clock. Operates in output mode in master mode and input mode for slave mode. (I2S Master/Slave 2)); 3=GPIO (General purpose I/O); 4=UART0RX (UART receive input (UART 0)); 5=UART1RX (UART receive input (UART 1)); 6=CT47 (Timer/Counter input or output; Selection of direction is done via CTIMER register settings.); 7=NCE47 (IOMSTR/MSPI N Chip Select. Polarity is determined by CE_POLARITY field); 8=OBSBUS15 (Observation bus bit 15); 10=I2S0_CLK (Bidirectional I2S Bit clock. Operates in output mode in master mode and input mode for slave mode. (I2S Master/Slave 2)); 11=FPIO (Fast PIO)
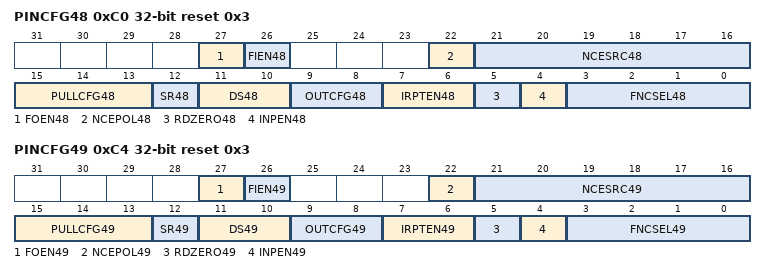
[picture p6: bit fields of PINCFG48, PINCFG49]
0xC0 PINCFG48 reset 0x3 — Controls the operation of GPIO pin 48.
  [27] FOEN48 — Force output enable active regardless of function selected. Otherwise the selected function will enable the output only when needed
  [26] FIEN48 — Force input enable active regardless of function selected. Otherwise the selected function will enable the input only when needed
  [22] NCEPOL48 — Polarity select for NCE for GPIO 48
    values as PINCFG24.NCEPOL24
  [21:16] NCESRC48 — IOMSTR/MSPI N Chip Select 48, DISP control signals DE, CSX, and CS. Polarity is determined by CE_POLARITY field
    values as PINCFG24.NCESRC24
  [15:13] PULLCFG48 — Pullup/Pulldown configuration for GPIO 48
    values as PINCFG24.PULLCFG24
  [12] SR48 — Configure the slew rate
  [11:10] DS48 — Drive strength selection for GPIO 48
    values as PINCFG24.DS24
  [9:8] OUTCFG48 — Pin IO mode selection for GPIO pin 48
    values as PINCFG24.OUTCFG24
  [7:6] IRPTEN48 — Interrupt enable for GPIO 48
    values as PINCFG24.IRPTEN24
  [5] RDZERO48 — Return 0 for read data on GPIO 48
  [4] INPEN48 — Input enable for GPIO 48
  [3:0] FNCSEL48 — Function select for GPIO pin 48
    0=M5SDAWIR3 (Serial I2C Master Data I/O (I2C Mode) Serial SPI Master Data I/O (SPI 3 wire mode) (IOM 5)); 1=M5MOSI (Serial SPI Master MOSI output (IOM 5)); 2=I2S1_DATA (Bidirectional I2S Data. Operates in output mode in master mode and input mode for slave mode. (I2S Master/Slave 2)); 3=GPIO (General purpose I/O); 4=UART2RX (UART receive input (UART 2)); 5=UART3RX (UART receive input (UART 3)); 6=CT48 (Timer/Counter input or output; Selection of direction is done via CTIMER register settings.); 7=NCE48 (IOMSTR/MSPI N Chip Select. Polarity is determined by CE_POLARITY field); 8=OBSBUS0 (Observation bus bit 0); 9=I2S1_SDOUT (I2S Data output (I2S Master/Slave 2)); 10=I2S0_SDOUT (I2S Data output (I2S Master/Slave 2)); 11=FPIO (Fast PIO)
0xC4 PINCFG49 reset 0x3 — Controls the operation of GPIO pin 49.
  [27] FOEN49 — Force output enable active regardless of function selected. Otherwise the selected function will enable the output only when needed
  [26] FIEN49 — Force input enable active regardless of function selected. Otherwise the selected function will enable the input only when needed
  [22] NCEPOL49 — Polarity select for NCE for GPIO 49
    values as PINCFG24.NCEPOL24
  [21:16] NCESRC49 — IOMSTR/MSPI N Chip Select 49, DISP control signals DE, CSX, and CS. Polarity is determined by CE_POLARITY field
    values as PINCFG24.NCESRC24
  [15:13] PULLCFG49 — Pullup/Pulldown configuration for GPIO 49
    values as PINCFG24.PULLCFG24
  [12] SR49 — Configure the slew rate
  [11:10] DS49 — Drive strength selection for GPIO 49
    values as PINCFG24.DS24
  [9:8] OUTCFG49 — Pin IO mode selection for GPIO pin 49
    values as PINCFG24.OUTCFG24
  [7:6] IRPTEN49 — Interrupt enable for GPIO 49
    values as PINCFG24.IRPTEN24
  [5] RDZERO49 — Return 0 for read data on GPIO 49
  [4] INPEN49 — Input enable for GPIO 49
  [3:0] FNCSEL49 — Function select for GPIO pin 49
    0=M5MISO (Serial SPI MASTER MISO input (IOM 5)); 1=TRIG0 (ADC trigger input); 2=I2S1_WS (Bidirectional I2S L/R clock. Operates in output mode in master mode and input mode for slave mode. (I2S Master/Slave 2)); 3=GPIO (General purpose I/O); 4=UART0RTS (UART Request to Send (RTS) (UART 0)); 5=UART1RTS (UART Request to Send (RTS) (UART 1)); 6=CT49 (Timer/Counter input or output; Selection of direction is done via CTIMER register settings.); 7=NCE49 (IOMSTR/MSPI N Chip Select. Polarity is determined by CE_POLARITY field); 8=OBSBUS1 (Observation bus bit 1); 10=I2S0_WS (Bidirectional I2S L/R clock. Operates in output mode in master mode and input mode for slave mode. (I2S Master/Slave 2)); 11=FPIO (Fast PIO)
